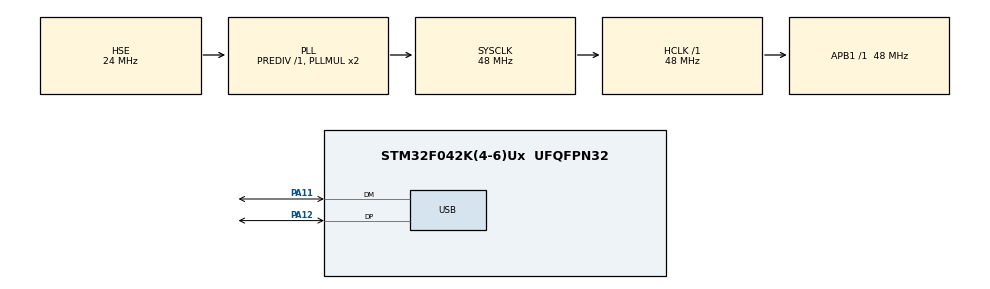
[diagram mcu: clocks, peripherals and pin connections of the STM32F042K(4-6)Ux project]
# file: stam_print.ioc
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FREERTOS.BinarySemaphores01=myBinarySem01,Dynamic,NULL
FREERTOS.Tasks01=defaultTask,0,128,StartDefaultTask,Default,NULL,Dynamic,NULL,NULL;myTask02,0,128,StartTask02,Default,NULL,Dynamic,NULL,NULL
Mcu.Family=STM32F0
Mcu.Name=STM32F042K(4-6)Ux
Mcu.Package=UFQFPN32
NVIC.TIM3_IRQn=true\:0\:0\:false\:false\:true\:false\:false
NVIC.TimeBase=TIM3_IRQn
NVIC.TimeBaseIP=TIM3
PA11.Mode=Device
PA11.Signal=USB_DM
PA12.Mode=Device
PA12.Signal=USB_DP
PF0-OSC_IN.Mode=HSE-External-Oscillator
PF0-OSC_IN.Signal=RCC_OSC_IN
PF1-OSC_OUT.Mode=HSE-External-Oscillator
PF1-OSC_OUT.Signal=RCC_OSC_OUT
ProjectManager.HeapSize=0x0
ProjectManager.StackSize=0x400
ProjectManager.TargetToolchain=TrueSTUDIO
RCC.AHBFreq_Value=48000000
RCC.APB1Freq_Value=48000000
RCC.APB1TimFreq_Value=48000000
RCC.HCLKFreq_Value=48000000
RCC.HSE_VALUE=24000000
RCC.PLLSourceVirtual=RCC_PLLSOURCE_HSE
RCC.SYSCLKFreq_VALUE=48000000
RCC.SYSCLKSource=RCC_SYSCLKSOURCE_PLLCLK
VP_FREERTOS_VS_ENABLE.Mode=Enabled
VP_SYS_VS_tim3.Mode=TIM3
board=custom

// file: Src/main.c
/* USER CODE BEGIN Header */
/**
  ******************************************************************************
  * @file           : main.c
  * @brief          : Main program body
  ******************************************************************************
  * This notice applies to any and all portions of this file
  * that are not between comment pairs USER CODE BEGIN and
  * USER CODE END. Other portions of this file, whether
  * inserted by the user or by software development tools
  * are owned by their respective copyright owners.
  *
  * Copyright (c) 2019 STMicroelectronics International N.V.
  * All rights reserved.
  *
  * Redistribution and use in source and binary forms, with or without
  * modification, are permitted, provided that the following conditions are met:
  *
  * 1. Redistribution of source code must retain the above copyright notice,
  *    this list of conditions and the following disclaimer.
  * 2. Redistributions in binary form must reproduce the above copyright notice,
  *    this list of conditions and the following disclaimer in the documentation
  *    and/or other materials provided with the distribution.
  * 3. Neither the name of STMicroelectronics nor the names of other
  *    contributors to this software may be used to endorse or promote products
  *    derived from this software without specific written permission.
  * 4. This software, including modifications and/or derivative works of this
  *    software, must execute solely and exclusively on microcontroller or
  *    microprocessor devices manufactured by or for STMicroelectronics.
  * 5. Redistribution and use of this software other than as permitted under
  *    this license is void and will automatically terminate your rights under
  *    this license.
  *
  * THIS SOFTWARE IS PROVIDED BY STMICROELECTRONICS AND CONTRIBUTORS "AS IS"
  * AND ANY EXPRESS, IMPLIED OR STATUTORY WARRANTIES, INCLUDING, BUT NOT
  * LIMITED TO, THE IMPLIED WARRANTIES OF MERCHANTABILITY, FITNESS FOR A
  * PARTICULAR PURPOSE AND NON-INFRINGEMENT OF THIRD PARTY INTELLECTUAL PROPERTY
  * RIGHTS ARE DISCLAIMED TO THE FULLEST EXTENT PERMITTED BY LAW. IN NO EVENT
  * SHALL STMICROELECTRONICS OR CONTRIBUTORS BE LIABLE FOR ANY DIRECT, INDIRECT,
  * INCIDENTAL, SPECIAL, EXEMPLARY, OR CONSEQUENTIAL DAMAGES (INCLUDING, BUT NOT
  * LIMITED TO, PROCUREMENT OF SUBSTITUTE GOODS OR SERVICES; LOSS OF USE, DATA,
  * OR PROFITS; OR BUSINESS INTERRUPTION) HOWEVER CAUSED AND ON ANY THEORY OF
  * LIABILITY, WHETHER IN CONTRACT, STRICT LIABILITY, OR TORT (INCLUDING
  * NEGLIGENCE OR OTHERWISE) ARISING IN ANY WAY OUT OF THE USE OF THIS SOFTWARE,
  * EVEN IF ADVISED OF THE POSSIBILITY OF SUCH DAMAGE.
  *
  ******************************************************************************
  */
/* USER CODE END Header */

#include "main.h"
#include "cmsis_os.h"

/* USER CODE BEGIN Includes */
#include "usb.h"
/* USER CODE END Includes */

/* USER CODE BEGIN PD */
#define USB_PRINT(x) usb_tx_post(x,sizeof(x))

/* USER CODE END PD */

PCD_HandleTypeDef hpcd_USB_FS;

osThreadId defaultTaskHandle;
osThreadId myTask02Handle;
osSemaphoreId myBinarySem01Handle;
/* USER CODE BEGIN PV */
extern usbd_device udev;

/* USER CODE END PV */

void SystemClock_Config(void);
static void MX_GPIO_Init(void);
static void MX_USB_PCD_Init(void);
void StartDefaultTask(void const * argument);
void StartTask02(void const * argument);

int main(void)
{

  /* MCU Configuration--------------------------------------------------------*/

  /* Reset of all peripherals, Initializes the Flash interface and the Systick. */
  HAL_Init();

  /* Configure the system clock */
  SystemClock_Config();

  /* Initialize all configured peripherals */
  MX_GPIO_Init();
  MX_USB_PCD_Init();
  /* USER CODE BEGIN 2 */
  cdc_init_usbd();
  usbd_enable(&udev, true);
  usbd_connect(&udev, true);

  HAL_NVIC_EnableIRQ(USB_IRQn);
  /* USER CODE END 2 */

  /* Create the semaphores(s) */
  /* definition and creation of myBinarySem01 */
  osSemaphoreDef(myBinarySem01);
  myBinarySem01Handle = osSemaphoreCreate(osSemaphore(myBinarySem01), 1);

  /* Create the thread(s) */
  /* definition and creation of defaultTask */
  osThreadDef(defaultTask, StartDefaultTask, osPriorityNormal, 0, 128);
  defaultTaskHandle = osThreadCreate(osThread(defaultTask), NULL);

  /* definition and creation of myTask02 */
  osThreadDef(myTask02, StartTask02, osPriorityNormal, 0, 128);
  myTask02Handle = osThreadCreate(osThread(myTask02), NULL);

  /* Start scheduler */
  osKernelStart();

  /* We should never get here as control is now taken by the scheduler */

  /* Infinite loop */
  while (1)
  {

  }
}

void SystemClock_Config(void)
{
  RCC_OscInitTypeDef RCC_OscInitStruct = {0};
  RCC_ClkInitTypeDef RCC_ClkInitStruct = {0};
  RCC_PeriphCLKInitTypeDef PeriphClkInit = {0};

  /**Initializes the CPU, AHB and APB busses clocks
  */
  RCC_OscInitStruct.OscillatorType = RCC_OSCILLATORTYPE_HSI48|RCC_OSCILLATORTYPE_HSE;
  RCC_OscInitStruct.HSEState = RCC_HSE_ON;
  RCC_OscInitStruct.HSI48State = RCC_HSI48_ON;
  RCC_OscInitStruct.PLL.PLLState = RCC_PLL_ON;
  RCC_OscInitStruct.PLL.PLLSource = RCC_PLLSOURCE_HSE;
  RCC_OscInitStruct.PLL.PLLMUL = RCC_PLL_MUL2;
  RCC_OscInitStruct.PLL.PREDIV = RCC_PREDIV_DIV1;
  if (HAL_RCC_OscConfig(&RCC_OscInitStruct) != HAL_OK)
  {
    Error_Handler();
  }
  /**Initializes the CPU, AHB and APB busses clocks
  */
  RCC_ClkInitStruct.ClockType = RCC_CLOCKTYPE_HCLK|RCC_CLOCKTYPE_SYSCLK
                              |RCC_CLOCKTYPE_PCLK1;
  RCC_ClkInitStruct.SYSCLKSource = RCC_SYSCLKSOURCE_PLLCLK;
  RCC_ClkInitStruct.AHBCLKDivider = RCC_SYSCLK_DIV1;
  RCC_ClkInitStruct.APB1CLKDivider = RCC_HCLK_DIV1;

  if (HAL_RCC_ClockConfig(&RCC_ClkInitStruct, FLASH_LATENCY_1) != HAL_OK)
  {
    Error_Handler();
  }
  PeriphClkInit.PeriphClockSelection = RCC_PERIPHCLK_USB;
  PeriphClkInit.UsbClockSelection = RCC_USBCLKSOURCE_HSI48;

  if (HAL_RCCEx_PeriphCLKConfig(&PeriphClkInit) != HAL_OK)
  {
    Error_Handler();
  }
}

static void MX_USB_PCD_Init(void)
{

  hpcd_USB_FS.Instance = USB;
  hpcd_USB_FS.Init.dev_endpoints = 8;
  hpcd_USB_FS.Init.speed = PCD_SPEED_FULL;
  hpcd_USB_FS.Init.ep0_mps = DEP0CTL_MPS_64;
  hpcd_USB_FS.Init.phy_itface = PCD_PHY_EMBEDDED;
  hpcd_USB_FS.Init.low_power_enable = DISABLE;
  hpcd_USB_FS.Init.lpm_enable = DISABLE;
  hpcd_USB_FS.Init.battery_charging_enable = DISABLE;
  if (HAL_PCD_Init(&hpcd_USB_FS) != HAL_OK)
  {
    Error_Handler();
  }

}

static void MX_GPIO_Init(void)
{

  /* GPIO Ports Clock Enable */
  __HAL_RCC_GPIOF_CLK_ENABLE();
  __HAL_RCC_GPIOA_CLK_ENABLE();

}

void StartDefaultTask(void const * argument)
{

  /* USER CODE BEGIN 5 */
  /* Infinite loop */
  for(;;)
  {
	USB_PRINT("hello from thread 1!\n\r");
    osDelay(1500);
  }
  /* USER CODE END 5 */
}

void StartTask02(void const * argument)
{
  /* USER CODE BEGIN StartTask02 */
  /* Infinite loop */
  for(;;)
  {
	USB_PRINT("hello from thread 2!\n\r");
    osDelay(1200);
  }
  /* USER CODE END StartTask02 */
}

void HAL_TIM_PeriodElapsedCallback(TIM_HandleTypeDef *htim)
{
  if (htim->Instance == TIM3) {
    HAL_IncTick();
  }
}

void Error_Handler(void)
{
}

/************************ (C) COPYRIGHT STMicroelectronics *****END OF FILE****/
